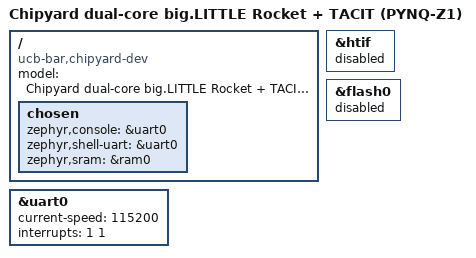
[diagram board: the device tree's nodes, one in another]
/dts-v1/;

/*
 * Dual-core big.LITTLE Rocket + TACIT on a PYNQ-Z1, as generated by Chipyard's
 * PynqZ2RocketBigLittleTacitConfig.
 *
 * Transcribed from the DTS Chipyard emits alongside the Verilog, at
 *   generated-src/chipyard.harness.TestHarness.PynqZ2RocketBigLittleTacitConfig/*.dts
 * That file is ground truth; anything here that disagrees with it is a bug here.
 *
 * WHAT THE GENERATED DTS SAYS, and why each line matters for SMP:
 *
 *   cpu@0  d/i-cache-size 16384, mmu-type "riscv,sv39", tlb-split   <- the BIG core
 *   cpu@1  d/i-cache-size  4096, no mmu-type, no tlb-split          <- the LITTLE core
 *   both   riscv,isa = "rv64imaczicsr_zifencei_zihpm_xrocket"
 *
 * The ISA strings are IDENTICAL, which is the whole point of using WithNSmallCores rather
 * than a different core family: one image, one ABI, one Zephyr SMP build covers both.
 * The difference is microarchitectural (cache size, BTB, TLB, and supervisor mode, which
 * Zephyr does not use here -- it runs in M-mode with CONFIG_RISCV_PMP=n).
 *
 *   clint@2000000 interrupts-extended = <&L11 3 &L11 7 &L16 3 &L16 7>
 *     Both harts have MSIP (3) and MTIP (7). That is what Zephyr's CLINT IPI
 *     (CONFIG_RISCV_SMP_IPI_CLINT, selected automatically by the "sifive,clint0"
 *     compatible below) and the per-hart mtimecmp at 0x2004000 + 8*hartid need.
 *
 *   interrupt-controller@c000000 interrupts-extended = <&L11 11 &L11 9 &L16 11>
 *     NOTE THE ASYMMETRY: hart 0 has an M context (11) AND an S context (9); hart 1 has
 *     only an M context, because WithNSmallCores sets useVM = false. So the PLIC contexts
 *     are ctx0 = hart0/M, ctx1 = hart0/S, ctx2 = hart1/M.
 *     The shared chipyard-riscv.dtsi lists <&hlicN 11 &hlicN 9> per hart, so its M-context
 *     indices are 0, 2, 4, ... -- and Zephyr's PLIC driver builds hart_context[] from
 *     exactly those indices (HART_CONTEXTS keeps index i when irq[i] == the PLIC's own
 *     irqn, 11). hart0 -> 0 and hart1 -> 2, which is what this hardware actually has.
 *
 * The shared dtsi declares eight status="okay" cpu nodes; only two exist here. That is
 * harmless and is left alone deliberately: Zephyr only ever touches the first
 * CONFIG_MP_MAX_NUM_CPUS of them (arch_kernel_init() walks cpu_node_list only up to
 * arch_num_cpus()), and pruning the extra nodes would leave the clint/plic/mtimer
 * interrupts-extended entries pointing at non-okay nodes for no benefit.
 *
 * Console: Rocket's SiFive UART is cross-connected in the PL to PS UART1 on EMIO, so its
 * output appears on the Linux side as /dev/ttyPS1 at 115200. See fpga/pynq-z2/docs/UART.md.
 */

#include <chipyard/chipyard-riscv64.dtsi>

/ {
	model = "Chipyard dual-core big.LITTLE Rocket + TACIT (PYNQ-Z1)";
	compatible = "ucb-bar,chipyard-dev";

	chosen {
		zephyr,console = &uart0;
		zephyr,shell-uart = &uart0;
		zephyr,sram = &ram0;
	};
};

&uart0 {
	status = "okay";
	current-speed = <115200>;
	/*
	 * PLIC source 1, NOT the 3 the shared chipyard dtsi assumes. The generated DTS says
	 * `interrupts = <1>` with `riscv,ndev = <1>` -- this SoC has exactly one PLIC device
	 * and the UART is it.
	 */
	interrupts = <1 1>;
};

/* HTIF is a simulator transport: it needs a host polling tohost/fromhost. On the FPGA the
 * console is a real UART, so leave it off. */
&htif {
	status = "disabled";
};

&flash0 {
	status = "disabled";
};
